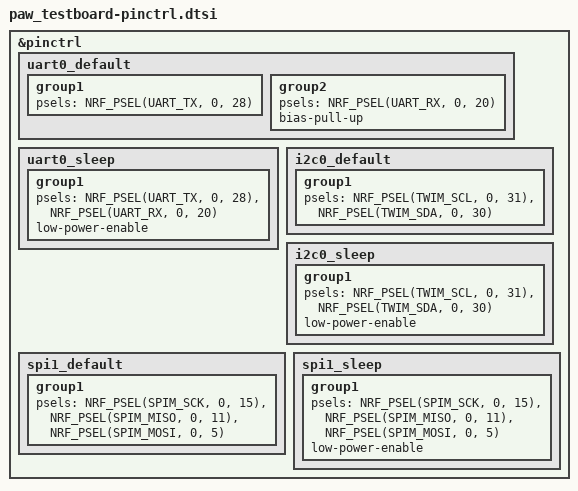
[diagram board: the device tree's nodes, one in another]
&pinctrl {
	uart0_default: uart0_default {
		group1 {
			psels = <NRF_PSEL(UART_TX, 0, 28)>;
		};
		group2 {
			psels = <NRF_PSEL(UART_RX, 0, 20)>;
			bias-pull-up;
		};
	};

	uart0_sleep: uart0_sleep {
		group1 {
			psels = <NRF_PSEL(UART_TX, 0, 28)>,
				<NRF_PSEL(UART_RX, 0, 20)>;
			low-power-enable;
		};
	};

	i2c0_default: i2c0_default {
		group1 {
			psels = <NRF_PSEL(TWIM_SCL, 0, 31)>,
				<NRF_PSEL(TWIM_SDA, 0, 30)>;
		};
	};

	i2c0_sleep: i2c0_sleep {
		group1 {
			psels = <NRF_PSEL(TWIM_SCL, 0, 31)>,
				<NRF_PSEL(TWIM_SDA, 0, 30)>;
			low-power-enable;
		};
	};

	spi1_default: spi1_default {
		group1 {
			psels = <NRF_PSEL(SPIM_SCK, 0, 15)>,
				<NRF_PSEL(SPIM_MISO, 0, 11)>,
				<NRF_PSEL(SPIM_MOSI, 0, 5)>;
		};
	};

	spi1_sleep: spi1_sleep {
		group1 {
			psels = <NRF_PSEL(SPIM_SCK, 0, 15)>,
				<NRF_PSEL(SPIM_MISO, 0, 11)>,
				<NRF_PSEL(SPIM_MOSI, 0, 5)>;
				low-power-enable;
		};
	};
};
